# DSS0_COMMON register map
Vendor: Texas Instruments
Peripheral module from a debugger description file (folder J722S).
Registers are 32-bit, read-write, reset 0x0 unless marked. A register's access mark holds for its fields unless they carry their own. Offsets are as the file gives them; lines under a group give offsets from that group; [hi:lo] are bit positions; {n}, {i} and the like mark numbered series; 'fields as' and 'values as' point back to an identical list; <NAME> marks a mode.

## DSS0_COMMON
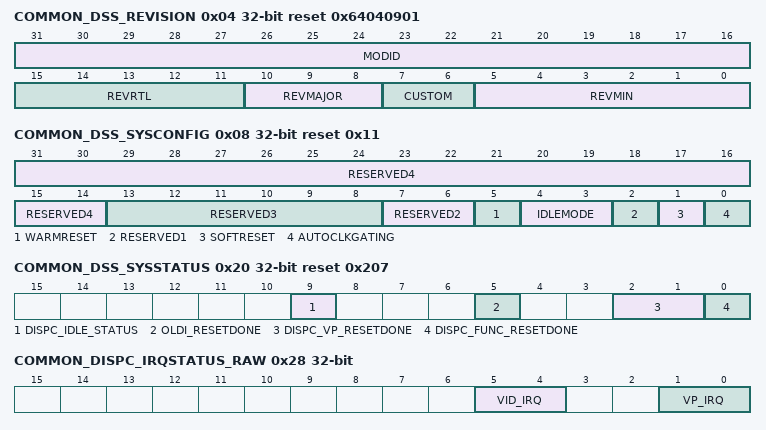
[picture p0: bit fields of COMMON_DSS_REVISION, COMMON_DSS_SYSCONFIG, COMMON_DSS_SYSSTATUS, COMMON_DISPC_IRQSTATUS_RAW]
0x04 COMMON_DSS_REVISION ro reset 0x64040901 — This register contains the K3_DSS revision number
  [31:16] MODID — Module ID Field
  [15:11] REVRTL — RTL Revision
  [10:8] REVMAJOR — Major Revision
  [7:6] CUSTOM
  [5:0] REVMIN — Minor Revision
0x08 COMMON_DSS_SYSCONFIG access per field reset 0x11 — This register controls various parameters related to software reset and IP idle
  [31:14] RESERVED4 ro — Write 0's for future compatibility. Read returns 0
  [13:8] RESERVED3 ro — Write 0's for future compatibility. Read returns 0
  [7:6] RESERVED2 ro — Write 0's for future compatibility. Read returns 0
  [5] WARMRESET rw — Warm reset. Setting this bit to 1 triggers a module warm reset. The bit is automatically reset by the hardware. During read, it always returns 0. The warm reset keeps the configuration registers unchanged
  [4:3] IDLEMODE rw — Deprecated
  [2] RESERVED1 ro — Write 0's for future compatibility. Read returns 0
  [1] SOFTRESET rw — Software reset. Setting this bit to 1 triggers a module reset. The bit is automatically reset by the hardware. During read, it always returns 0
  [0] AUTOCLKGATING rw — Internal clock gating strategy
0x20 COMMON_DSS_SYSSTATUS ro reset 0x207 — This register provides status information about the module, excluding the interrupt status information
  [9] DISPC_IDLE_STATUS — Idle status of DISPC
  [5] OLDI_RESETDONE — Reset status of OLDI
  [2:1] DISPC_VP_RESETDONE — Reset status of VP pixel clock domain
  [0] DISPC_FUNC_RESETDONE — Reset status of DISPC Functional clock domain
0x24 COMMON_DISPC_IRQ_EOI wo — End-Of-Interrupt register, to be used if pulse interrupts are used
  [0] EOI — Write 1 to acknowledge a pulse IRQ
0x28 COMMON_DISPC_IRQSTATUS_RAW access not given — RAW Interrupt status. Raw status is set even if interrupt is not enabled. Write 1 to set the RAW status
  [5:4] VID_IRQ — VID IRQ STATUS. Register indicates the VIDEO pipeline[s] interrupt events (access R/W1TS)
  [1:0] VP_IRQ — VP IRQ STATUS. Register indicates the Video Port[s] interrupt events (access R/W1TS)
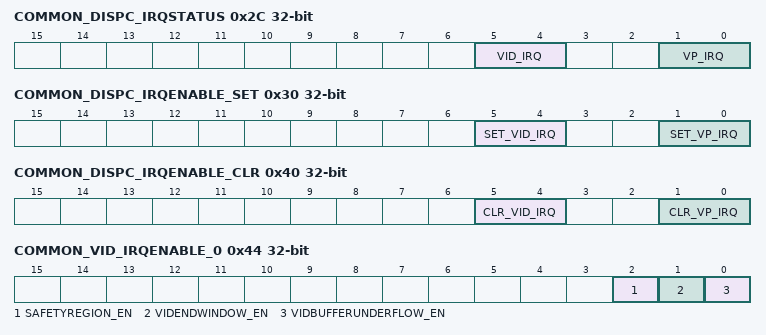
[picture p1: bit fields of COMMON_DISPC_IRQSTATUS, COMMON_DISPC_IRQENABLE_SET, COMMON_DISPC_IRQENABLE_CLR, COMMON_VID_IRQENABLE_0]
0x2C COMMON_DISPC_IRQSTATUS access not given — Interrupt status. Enabled status, isn't set unless event is enabled. Write 1 to clear the status after interrupt has been serviced. RAW status also gets cleared, i.e. even if not enabled
  [5:4] VID_IRQ — VID IRQ STATUS. Register indicates the VIDEO pipeline[s] interrupt events (access R/W1TC)
  [1:0] VP_IRQ — VP IRQ STATUS. Register indicates the Video Port[s] interrupt events (access R/W1TC)
0x30 COMMON_DISPC_IRQENABLE_SET access not given — SET Interrupt enable. Write 1 to set interrupt enable. Readout equal to corresponding _CLR register
  [5:4] SET_VID_IRQ — VID IRQ (access R/W1TS)
  [1:0] SET_VP_IRQ — VP IRQ (access R/W1TS)
0x40 COMMON_DISPC_IRQENABLE_CLR access not given — CLR Interrupt enable. Write 1 to clear interrupt enable
  [5:4] CLR_VID_IRQ — VID IRQ (access R/W1TC)
  [1:0] CLR_VP_IRQ — VP IRQ (access R/W1TC)
0x44 COMMON_VID_IRQENABLE_0 — This register allows to mask/unmask the VID_0 internal sources of interrupt, on an event-by-event basis
  [2] SAFETYREGION_EN — Safety Feature IRQ. This is raised when FrameFreeze is detected or data mismatch occurs within the safety region
  [1] VIDENDWINDOW_EN — Video End Window. This is raised by the DMA engine when the full video data has been sent to the pipeline
  [0] VIDBUFFERUNDERFLOW_EN — Video DMA Buffer Underflow. This is raised when the DMA buffer does not have the data requested by the Video pipeline
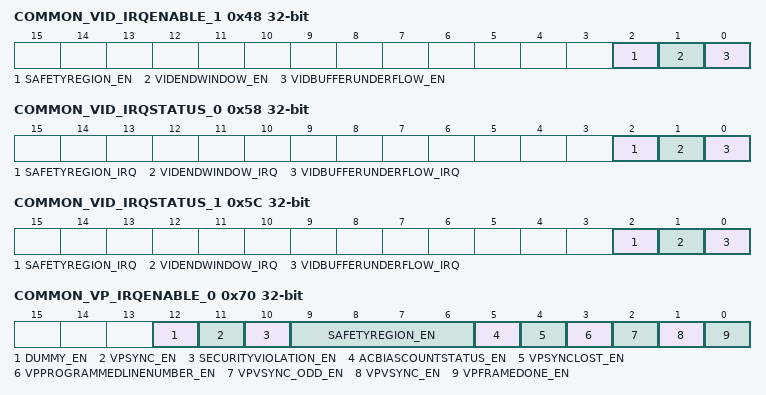
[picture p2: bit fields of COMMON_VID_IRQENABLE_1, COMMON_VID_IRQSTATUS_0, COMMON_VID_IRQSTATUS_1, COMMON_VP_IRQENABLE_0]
0x48 COMMON_VID_IRQENABLE_1 — This register allows to mask/unmask the VIDL_0 internal sources of interrupt, on an event-by-event basis
  fields as COMMON_VID_IRQENABLE_0
0x58 COMMON_VID_IRQSTATUS_0 access not given — This register groups all the status of the VID_0 internal events that generate an interrupt. Write 1 to a clear a bit field
  [2] SAFETYREGION_IRQ — Safety Feature IRQ. This is raised when FrameFreeze is detected or data mismatch occurs within the safety region (access R/W1TC)
  [1] VIDENDWINDOW_IRQ — Video End Window. This is raised by the DMA engine when the full video data has been sent to the pipeline (access R/W1TC)
  [0] VIDBUFFERUNDERFLOW_IRQ — Video DMA Buffer Underflow. This is raised when the DMA buffer does not have the data requested by the Video pipeline (access R/W1TC)
0x5C COMMON_VID_IRQSTATUS_1 access not given — This register groups all the status of the VIDL_0 internal events that generate an interrupt. Write 1 to a clear a bit field
  fields as COMMON_VID_IRQSTATUS_0
0x70 COMMON_VP_IRQENABLE_0 — This register allows to mask/unmask the VP_0 internal sources of interrupt, on an event-by-event basis
  [12] DUMMY_EN — Dummy IRQ for future use
  [11] VPSYNC_EN — Go bit clear event
  [10] SECURITYVIOLATION_EN — Security Violation interrupt for OVR/VP. Non-secure OVR/VP connected to secure VID
  [9:6] SAFETYREGION_EN — Safety Feature IRQ. This is raised when FrameFreeze is detected or data mismatch occurs within the safety region
  [5] ACBIASCOUNTSTATUS_EN — AC BIAS transition counter has decremented to zero
  [4] VPSYNCLOST_EN — Synchronization Lost for Video Port
  [3] VPPROGRAMMEDLINENUMBER_EN — Programmed Line Number. It indicates that the scan of the display has reached the programmed user line number
  [2] VPVSYNC_ODD_EN — VSYNC for odd field from interlace mode only
  [1] VPVSYNC_EN — Vertical Synchronization for VP
  [0] VPFRAMEDONE_EN — Frame Done for Video Port. VP output has been disabled by user. All the data have been sent
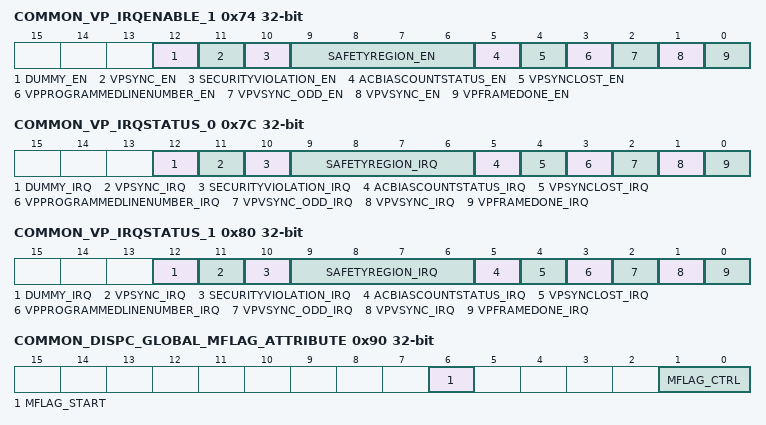
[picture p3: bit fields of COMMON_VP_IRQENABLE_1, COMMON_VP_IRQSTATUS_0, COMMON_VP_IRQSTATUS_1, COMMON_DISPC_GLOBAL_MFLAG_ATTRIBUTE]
0x74 COMMON_VP_IRQENABLE_1 — This register allows to mask/unmask the VP_1 internal sources of interrupt, on an event-by-event basis
  fields as COMMON_VP_IRQENABLE_0
0x7C COMMON_VP_IRQSTATUS_0 access not given — This register groups all the status of the VP_0 internal events that generate an interrupt. Write 1 to a given bit resets this bit
  [12] DUMMY_IRQ — Dummy IRQ for future use (access R/W1TC)
  [11] VPSYNC_IRQ — Go bit clear event (access R/W1TC)
  [10] SECURITYVIOLATION_IRQ — Security Violation IRQ. Non-secure OVR/VP connected to secure VID (access R/W1TC)
  [9:6] SAFETYREGION_IRQ — Safety Feature IRQ. This is raised when FrameFreeze is detected or data mismatch occurs within the safety region (access R/W1TC)
  [5] ACBIASCOUNTSTATUS_IRQ — AC BIAS transition counter has decremented to zero (access R/W1TC)
  [4] VPSYNCLOST_IRQ — Synchronization Lost on VP output. The required data are not output at the correct time due to too short blanking periods or stall of at least one pipelines associated with VP output (access R/W1TC)
  [3] VPPROGRAMMEDLINENUMBER_IRQ — Programmed Line Number. It indicates that the scan of the display has reached the programmed user line number (access R/W1TC)
  [2] VPVSYNC_ODD_IRQ — VSYNC for odd field. For interlace mode only (access R/W1TC)
  [1] VPVSYNC_IRQ — Vertical Synchronization for VP output. It is used as VSYNC_EVEN in case of interlace mode (access R/W1TC)
  [0] VPFRAMEDONE_IRQ — Frame Done for VP. VP output has been disabled by user All the data have been sent (access R/W1TC)
0x80 COMMON_VP_IRQSTATUS_1 access not given — This register groups all the status of the VP_1 internal events that generate an interrupt. Write 1 to a given bit resets this bit
  fields as COMMON_VP_IRQSTATUS_0
0x90 COMMON_DISPC_GLOBAL_MFLAG_ATTRIBUTE — MFLAG control register
  [6] MFLAG_START — MFLAG_START for DMA initiator port
  [1:0] MFLAG_CTRL — MFLAG_CTRL for DMA initiator port
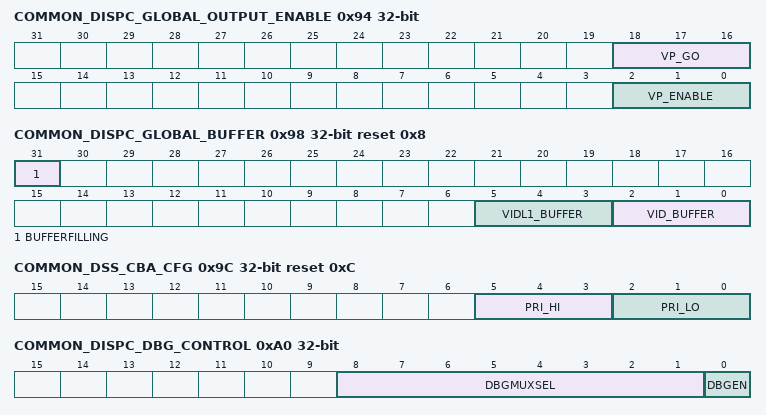
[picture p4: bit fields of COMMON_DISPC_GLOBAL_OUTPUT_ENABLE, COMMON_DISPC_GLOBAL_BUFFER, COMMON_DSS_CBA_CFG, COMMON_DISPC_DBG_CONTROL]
0x94 COMMON_DISPC_GLOBAL_OUTPUT_ENABLE — DISPC global output enable register. The ENABLE or GO bit for a particular output port is set when either the corresponding bit in this register is set or the corresponding bit within the sub-module is set. This register allows enabling multiple outputs synchronously [simultaneously], which is not possible if the ENABLE/GO bits are present only within the sub-module
  [18:16] VP_GO — Global GO Command for the VP[2:0] output. It is used to synchronize the pipelines associated with the VP output. wr: immediate
  [2:0] VP_ENABLE — Global VP[2:0] Enable
0x98 COMMON_DISPC_GLOBAL_BUFFER reset 0x8 — The register configures the DMA buffers allocations to the pipelines for DMA
  [31] BUFFERFILLING — Controls if the DMA buffers are re-filled only when the LOW threshold is reached or if all DMA buffers are re-filled when at least one of them reaches the LOW threshold
  [5:3] VIDL1_BUFFER — VIDL1 DMA buffer allocation to one of the pipelines
  [2:0] VID_BUFFER — VID DMA buffer allocation to one of the pipelines
0x9C COMMON_DSS_CBA_CFG reset 0xC — This register contains CBA specific config bits in DSS
  [5:3] PRI_HI — The value sent out on the PRI_HI bus from DSS to CBA Indicates the priority level for high-priority [MFLAG] transactions. Value of 0x0 indicates highest priority Value of 0x7 indicates lowest priority
  [2:0] PRI_LO — The value sent out on the PRI_LO bus from DSS to CBA Indicates the priority level for normal [non-MFLAG] transactions. Value of 0x0 indicates highest priority Value of 0x7 indicates lowest priority
0xA0 COMMON_DISPC_DBG_CONTROL — DISPC debug status control register
  [8:1] DBGMUXSEL — Mux select for the debug status
  [0] DBGEN — Enable debug ports
0xA4 COMMON_DISPC_DBG_STATUS ro — DISPC debug status register
  [31:0] DBGOUT — Debug status
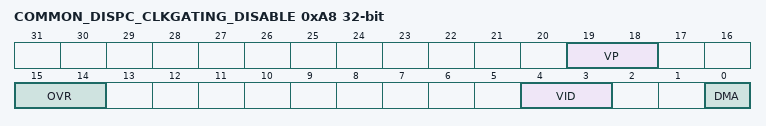
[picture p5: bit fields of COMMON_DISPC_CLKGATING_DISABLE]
0xA8 COMMON_DISPC_CLKGATING_DISABLE — Register to control clock gating at DISPC sub-module level
  [19:18] VP — Clock gating control for VP[2:0]
  [15:14] OVR — Clock gating control for OVR[2:0]
  [4:3] VID — Clock gating control for VID
  [0] DMA — Clock gating control for DMA
0xAC COMMON_DISPC_SECURE_DISABLE — Disable security settings throughout DSS IP. COMMON_1.DISPC_SECURE bits are honoured only if COMMON.DISPC_SECURE_DISABLE =0
  [0] SECURE_DISABLE — Secure disable bit
